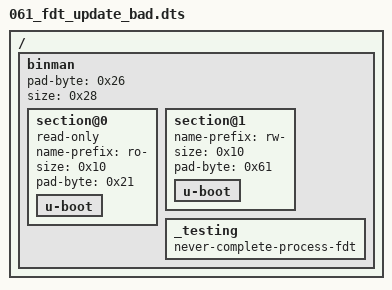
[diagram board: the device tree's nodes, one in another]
// SPDX-License-Identifier: GPL-2.0+
/dts-v1/;

/ {
	#address-cells = <1>;
	#size-cells = <1>;

	binman {
		pad-byte = <0x26>;
		size = <0x28>;
		section@0 {
			read-only;
			name-prefix = "ro-";
			size = <0x10>;
			pad-byte = <0x21>;

			u-boot {
			};
		};
		section@1 {
			name-prefix = "rw-";
			size = <0x10>;
			pad-byte = <0x61>;

			u-boot {
			};
		};
		_testing {
			never-complete-process-fdt;
		};
	};
};
